# NUC100BN_v1 register map
File version: 1.0
Registers are 32-bit, read-write, reset 0x0 unless marked. A register's access mark holds for its fields unless they carry their own. Offsets are from the block's base; [hi:lo] are bit positions; {n}, {i} and the like mark numbered series; 'fields as' and 'values as' point back to an identical list.

## ADC — ADC Register Map
Base 0x400E0000
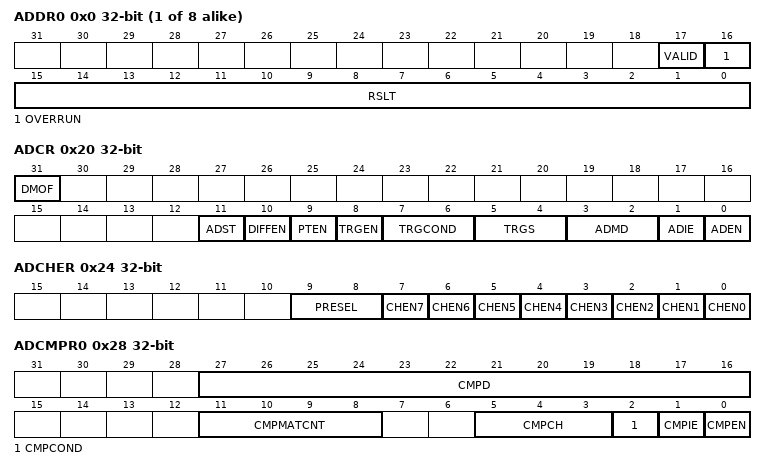
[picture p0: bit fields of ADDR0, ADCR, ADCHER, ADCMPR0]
{0x0+4i} ADDR{i} ro (i=0..7) — A/D Data Register {i}
  [17] VALID — Valid Flag. This bit is set to 1 when corresponding channel analog input conversion is completed and cleared by hardware after ADDR register is read. This is a read only bit
    0=Data in RSLT[15:0] bits is not valid; 1=Data in RSLT[15:0] bits is valid
  [16] OVERRUN — Over Run Flag. If converted data in RSLT[15:0] has not been read before new conversion result is loaded to this register, OVERRUN is set to 1 and previous conversion result is gone. It is cleared by hardware after ADDR register is read. This is a read only bit
    0=Data in RSLT[15:0] is recent conversion result; 1=Data in RSLT[15:0] is overwrite
  [15:0] RSLT — A/D Conversion Result. This field contains conversion result of ADC. For NuMicro( NUC100/NUC120 Medium density, RSLT[15:12] always read as 0. The following description is only support in NuMicro( NUC100/NUC120 Low Density: When DMOF bit (ADCR[31]) set to 0, 12-bit ADC conversion result with unsigned format will be filled in RSLT[11:0] and zero will be filled in RSLT[15:12]. When DMOF bit (ADCR[31]) set to 1, 12-bit ADC conversion result with 2'complement format will be filled in RSLT[11:0] and signed bits to will be filled in RSLT[15:12].
0x20 ADCR — A/D Control Register
  [31] DMOF — A/D Differential Input Mode Output Format (Only Supported in NuMicro( NUC100/NUC120 Low Density)
    0=A/D Conversion result will be filled in RSLT at ADDRx registers with unsigned format; 1=A/D Conversion result will be filled in RSLT at ADDRx registers with 2'complement format
  [11] ADST — A/D Conversion Start. ADST bit can be set to 1 from two sources: software and external pin STADC. ADST will be cleared to 0 by hardware automatically at the ends of single mode and single-cycle scan mode. In continuous scan mode, A/D conversion is continuously performed until software write 0 to this bit or chip reset.
    0=Conversion stopped and A/D converter enter idle state; 1=Conversion start
  [10] DIFFEN — Differential Input Mode Enable
    0=Single-end analog input mode; 1=Differential analog input mode
  [9] PTEN — PDMA Transfer Enable
    0=PDMA data transfer Disabled; 1=PDMA data transfer in ADDR 0~7 Enabled
  [8] TRGEN — External Trigger Enable. Enable or disable triggering of A/D conversion by external STADC pin. ADC external trigger function is only supported in single-cycle scan mode.
    0=Disabled; 1=Enabled
  [7:6] TRGCOND — External Trigger Conditions. These two bits decide external pin STADC trigger event is level or edge. The signal must be kept at stable state at least 8 PCLKs for level trigger and 4 PCLKs at high and low state for edge trigger.
    0=Low level; 1=High level; 2=Falling edge; 3=Rising edge
  [5:4] TRGS — Hardware Trigger Source. Software should disable TRGEN and ADST before change TRGS. In hardware trigger mode, the ADST bit is set by the external trigger from STADC.
    0=A/D conversion is started by external STADC pin
  [3:2] ADMD — A/D Converter Operation Mode. When changing the operation mode, software should disable ADST bit firstly.
    0=Single conversion; 2=Single-cycle scan; 3=Continuous scan
  [1] ADIE — A/D Interrupt Enable. A/D conversion end interrupt request is generated if ADIE bit is set to 1.
    0=A/D interrupt function Disabled; 1=A/D interrupt function Enabled
  [0] ADEN — A/D Converter Enable. Before starting A/D conversion function, this bit should be set to 1. Clear it to 0 to disable A/D converter analog circuit for saving power consumption.
    0=Disabled; 1=Enabled
0x24 ADCHER — A/D Channel Enable Register
  [9:8] PRESEL — Analog Input Channel 7 select. Note: When software selects the band-gap voltage as the analog input source of ADC channel 7, ADC clock rate needs to be limited to lower than 300 kHz.
    0=External analog input; 1=Internal band-gap voltage; 2=Internal temperature sensor
  [n] CHEN{n} (n=0..7) — Analog Input Channel {n} Enable
    0=Disabled; 1=Enabled
0x28 ADCMPR0 — A/D Compare Register 0
  [27:16] CMPD — Comparison Data. The 12-bit data is used to compare with conversion result of specified channel. The following description is only support in NuMicro( NUC100/NUC120 Low Density: When DMOF bit is set to 0, ADC comparator compares CMPD with conversion result with unsigned format. CMPD should be filled in unsigned format. When DMOF bit is set to 1, ADC comparator compares CMPD with conversion result with 2'complement format. CMPD should be filled in 2'complement format.
  [11:8] CMPMATCNT — Compare Match Count. When the specified A/D channel analog conversion result matches the compare condition defined by CMPCOND[2], the internal match counter will increase 1. When the internal counter reaches the value to (CMPMATCNT +1), the CMPFx bit will be set.
  [5:3] CMPCH — Compare Channel Selection
    {v}=Channel {v} conversion result is selected to be compared (v=0..7)
  [2] CMPCOND — Compare Condition. Note: When the internal counter reaches the value to (CMPMATCNT +1), the CMPFx bit will be set.
    0=Set the compare condition as that when a 12-bit A/D conversion result is less than the 12-bit CMPD (ADCMPRx[27:16]), the internal match counter will increase one; 1=Set the compare condition as that when a 12-bit A/D conversion result is greater or equal to the 12-bit CMPD (ADCMPRx[27:16]), the internal match counter will increase one
  [1] CMPIE — Compare Interrupt Enable. If the compare function is enabled and the compare condition matches the setting of CMPCOND and CMPMATCNT, CMPF bit will be asserted, in the meanwhile, if CMPIE is set to 1, a compare interrupt request is generated.
    0=Compare function interrupt Disabled; 1=Compare function interrupt Enabled
  [0] CMPEN — Compare Enable. Set this bit to 1 to enable ADC controller to compare CMPD[11:0] with specified channel conversion result when converted data is loaded into ADDR register.
    0=Compare function Disabled; 1=Compare function Enabled
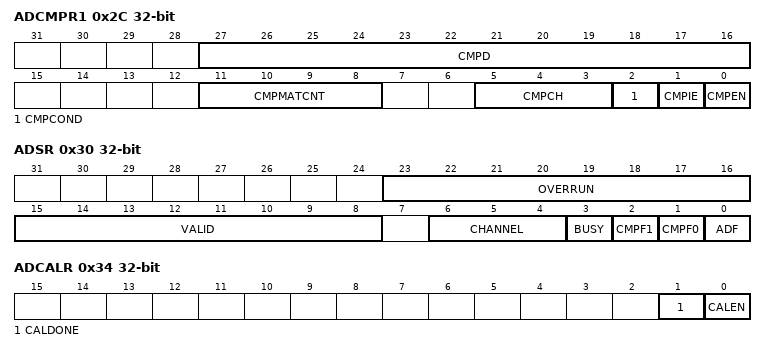
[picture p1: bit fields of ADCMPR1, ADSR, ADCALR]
0x2C ADCMPR1 — A/D Compare Register 1
  fields as ADCMPR0
0x30 ADSR — A/D Status Register
  [23:16] OVERRUN — Over Run flag. It is a mirror to OVERRUN bit in ADDRx. It is read only.
  [15:8] VALID — Data Valid flag. It is a mirror of VALID bit in ADDRx. It is read only.
  [6:4] CHANNEL — Current Conversion Channel. It is read only.
  [3] BUSY — BUSY/IDLE. This bit is mirror of as ADST bit in ADCR. It is read only.
    0=A/D converter is in idle state; 1=A/D converter is busy at conversion
  [2] CMPF1 — Compare Flag. When the selected channel A/D conversion result meets setting condition in ADCMPR1 then this bit is set to 1. And it is cleared by writing 1 to self.
    0=Conversion result in ADDR does not meet ADCMPR1 setting; 1=Conversion result in ADDR meets ADCMPR1 setting
  [1] CMPF0 — Compare Flag. When the selected channel A/D conversion result meets setting condition in ADCMPR0 then this bit is set to 1. And it is cleared by writing 1 to self.
    0=Conversion result in ADDR does not meet ADCMPR0 setting; 1=Conversion result in ADDR meets ADCMPR0 setting
  [0] ADF — A/D Conversion End Flag. A status flag that indicates the end of A/D conversion. ADF is set to 1 at these two conditions: 1. When A/D conversion ends in Single mode. 2. When A/D conversion ends on all specified channels in Scan mode. This flag can be cleared by writing 1 to itself.
0x34 ADCALR — A/D Calibration Register
  [1] CALDONE — Calibration Complete. When writing 0 to CALEN bit, CALDONE bit is cleared by hardware immediately. It is a read only bit.
    0=A/D converter has not been calibrated or calibration is in progress if CALEN bit is set; 1=A/D converter self-calibration is done
  [0] CALEN — Self-calibration Enable. Software can set this bit to 1 to enable A/D converter to do self-calibration function. It needs 127 ADC clocks to complete calibration. This bit must be kept at 1 after CALDONE asserted. Clearing this bit will disable self-calibration function.
    0=Self-calibration Disabled; 1=Self-calibration Enabled
0x40 ADPDMA ro — ADC PDMA Current Transfer Data
  [11:0] AD_PDMA — ADC PDMA Current Transfer Data Register. When PDMA transferring, read this register can monitor current PDMA transfer data. This is a read only register.
